# STM32U375 register map
File version: 1.0
CPU: CM33 r0p1, little endian, MPU, FPU, 4 interrupt priority bits
Registers are 32-bit, read-write, reset 0x0 unless marked. A register's access mark holds for its fields unless they carry their own. Offsets are from the block's base; [hi:lo] are bit positions; 'fields as' and 'values as' point back to an identical list.

## COMP — COMP1 Address block
Base 0x40045400
Same registers: SEC_COMP 0x50045400
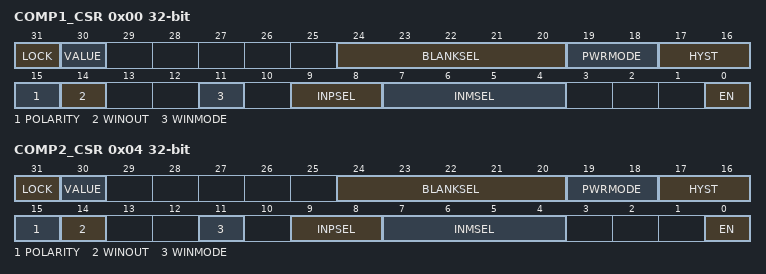
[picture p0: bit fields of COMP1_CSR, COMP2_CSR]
0x00 COMP1_CSR access per field — COMP1 control and status register
  [31] LOCK rw — This bit is set by software and cleared by reset. It locks the whole content of COMP1_CSR. 0: COMP1_CSR read/write bits can be written by software. 1: COMP1_CSR bits can be read but not written by software.
    0=COMP1_CSR read/write bits can be written by software; 1=COMP1_CSR bits can be read but not written by software
  [30] VALUE ro — This bit is read-only. It reflects the level of the COMP1 output after the polarity selector and blanking (see less than xe2 [Comparator_output_blanking_function/ID00-187] [number]/>).
  [24:20] BLANKSEL rw — This field is controlled by software (if not locked) and selects the blanking source: 00000: None (no blanking) 00001: tim1_oc5 00010: tim2_oc3 Others: Reserved
    0=None (no blanking); 1=tim1_oc5; 2=tim2_oc3
  [19:18] PWRMODE rw — Controlled by software (if not locked), selects the power consumption and, as a consequence, the speed of the COMP1. 00: High speed 01: Intermediate speed and power 10: Medium speed and power 11: Ultra-low-power
    0=High speed; 1=Intermediate speed and power; 2=Medium speed and power; 3=Ultra-low-power
  [17:16] HYST rw — Controlled by software (if not locked), selects the COMP1 hysteresis. 00: None 01: Low hysteresis 10: Medium hysteresis 11: High hysteresis
    0=None; 1=Low hysteresis; 2=Medium hysteresis; 3=High hysteresis
  [15] POLARITY rw — Controlled by software (if not locked), selects the COMP1 output polarity. 0: Noninverted 1: Inverted
    0=Noninverted; 1=Inverted
  [14] WINOUT rw — Controlled by software (if not locked), selects the COMP1 output. 0: COMP1_VALUE 1: COMP1_VALUE xOR COMP2_VALUE (required for window mode, see less than xe5 [Window_comparator/ID00-180] [number]/>)
    0=COMP1_VALUE; 1=COMP1_VALUE xOR COMP2_VALUE (required for window mode, see less than xe5 [Window_comparator/ID00-180] [number]/>)
  [11] WINMODE rw — Controlled by software (if not locked), selects the signal for the COMP1_INP input of the COMP1. 0: Signal selected with INPSEL[1:0] 1: COMP2_INP signal of COMP2 (required for window mode, see less than xe5 [Window_comparator/ID00-180] [number]/>)
    0=Signal selected with INPSEL[1:0]; 1=COMP2_INP signal of COMP2 (required for window mode, see less than xe5 [Window_comparator/ID00-180] [number]/>)
  [9:8] INPSEL rw — Controlled by software (if not locked), selects the signal for the noninverting input COMP1_INP (see less than xe6 [COMP_pins_and_internal_signals/IDTBL00-3] [number]/> for the assignment).
  [7:4] INMSEL rw — Controlled by software (if not locked), selects the signal for the inverting input COMP1_INM (see less than xe3 [COMP_pins_and_internal_signals/IDTBL00-15] [number]/> for the assignment).
  [0] EN rw — Controlled by software (if not locked), enables COMP1. 0: COMP1 disabled 1: COMP1 enabled
    0=COMP1 disabled; 1=COMP1 enabled
0x04 COMP2_CSR access per field — COMP2 control and status register
  [31] LOCK rw — This bit is set by software and cleared by reset. It locks the whole content of COMP2_CSR. 0: COMP2_CSR read/write bits can be written by software. 1: COMP2_CSR bits can be read but not written by software.
    0=COMP2_CSR read/write bits can be written by software; 1=COMP2_CSR bits can be read but not written by software
  [30] VALUE ro — This bit is read-only. It reflects the level of the COMP2 output after the polarity selector and blanking (see less than xe2 [Comparator_output_blanking_function/ID00-187] [number]/>).
  [24:20] BLANKSEL rw — Controlled by software (if not locked) and selects the blanking source: 00000: None (no blanking) 00001: tim3_oc4 Others: Reserved
    0=None (no blanking); 1=tim3_oc4
  [19:18] PWRMODE rw — Controlled by software (if not locked), selects the power consumption and, as a consequence, the speed of the COMP2. 00: High speed 01: Intermediate speed and power 10: Medium speed and power 11: Ultra-low-power
    values as COMP1_CSR.PWRMODE
  [17:16] HYST rw — Controlled by software (if not locked), selects the COMP2 hysteresis. 00: None 01: Low hysteresis 10: Medium hysteresis 11: High hysteresis
    values as COMP1_CSR.HYST
  [15] POLARITY rw — Controlled by software (if not locked), selects the COMP2 output polarity. 0: Noninverted 1: Inverted
    0=Noninverted; 1=Inverted
  [14] WINOUT rw — Controlled by software (if not locked), selects the COMP2 output. 0: COMP2_VALUE 1: COMP1_VALUE xOR COMP2_VALUE (required for window mode, see less than xe5 [Window_comparator/ID00-180] [number]/>)
    0=COMP2_VALUE; 1=COMP1_VALUE xOR COMP2_VALUE (required for window mode, see less than xe5 [Window_comparator/ID00-180] [number]/>)
  [11] WINMODE rw — Controlled by software (if not locked), selects the signal for the COMP2_INP input of the COMP2. 0: Signal selected with INPSEL[1:0] 1: COMP1_INP signal of COMP1 (required for window mode, see less than xe5 [Window_comparator/ID00-180] [number]/>)
    0=Signal selected with INPSEL[1:0]; 1=COMP1_INP signal of COMP1 (required for window mode, see less than xe5 [Window_comparator/ID00-180] [number]/>)
  [9:8] INPSEL rw — Controlled by software (if not locked), selects the signal for the noninverting input COMP2_INP (see less than xe4 [COMP_pins_and_internal_signals/IDTBL00-43] [number]/> for the assignment).
  [7:4] INMSEL rw — Controlled by software (if not locked), selects the signal for the inverting input COMP2_INM (see less than xe1 [COMP_pins_and_internal_signals/IDTBL00-55] [number]/> for the assignment).
  [0] EN rw — Controlled by software (if not locked), enables COMP2. 0: COMP2 disabled 1: COMP2 enabled
    0=COMP2 disabled; 1=COMP2 enabled

## Notices in the file
Copyright (c) 2025 STMicroelectronics.
SPDx-License-Identifier: Apache-2.0
Licensed under the Apache License, Version 2.0 (the "License");
you may not use this file except in compliance with the License.
You may obtain a copy of the License at
http://www.apache.org/licenses/LICENSE-2.0
Unless required by applicable law or agreed to in writing, software
distributed under the License is distributed on an "AS IS" BASIS,
WITHOUT WARRANTIES OR CONDITIONS OF ANY KIND, either express or implied.
See the License for the specific language governing permissions and
limitations under the License.
